# STM32F439ZIY6 register map
File version: 1.0
Registers are 32-bit, access not given, reset 0x0 unless marked. A register's access mark holds for its fields unless they carry their own. Offsets are from the block's base; [hi:lo] are bit positions; {n}, {i} and the like mark numbered series; 'fields as' and 'values as' point back to an identical list.

## DCMI
Base 0x50050000
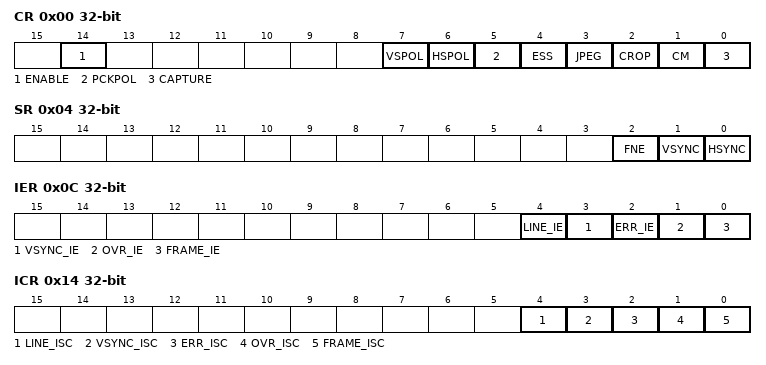
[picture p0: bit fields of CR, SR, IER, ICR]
0x00 CR
  [14] ENABLE, [7] VSPOL, [6] HSPOL, [5] PCKPOL, [4] ESS, [3] JPEG, [2] CROP, [1] CM, [0] CAPTURE
0x04 SR
  [2] FNE, [1] VSYNC, [0] HSYNC
0x08 RISR
0x0C IER
  [4] LINE_IE, [3] VSYNC_IE, [2] ERR_IE, [1] OVR_IE, [0] FRAME_IE
0x10 MISR
0x14 ICR
  [4] LINE_ISC, [3] VSYNC_ISC, [2] ERR_ISC, [1] OVR_ISC, [0] FRAME_ISC
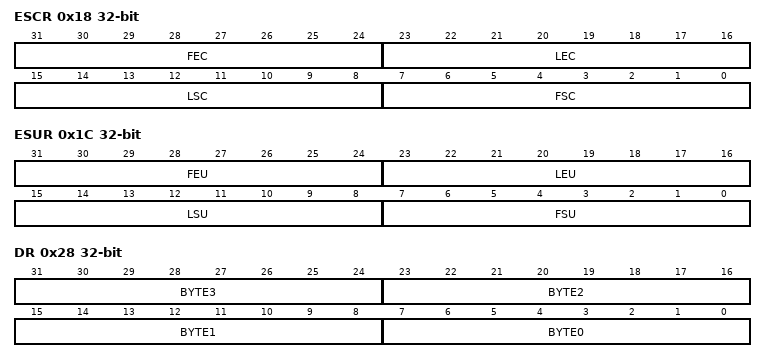
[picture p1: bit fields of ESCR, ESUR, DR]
0x18 ESCR
  [31:24] FEC, [23:16] LEC, [15:8] LSC, [7:0] FSC
0x1C ESUR
  [31:24] FEU, [23:16] LEU, [15:8] LSU, [7:0] FSU
0x20 CWSTRTR
0x24 CWSIZER
0x28 DR
  [8n+7:8n] BYTE{n} (n=0..3)

## CRYP
Base 0x50060000
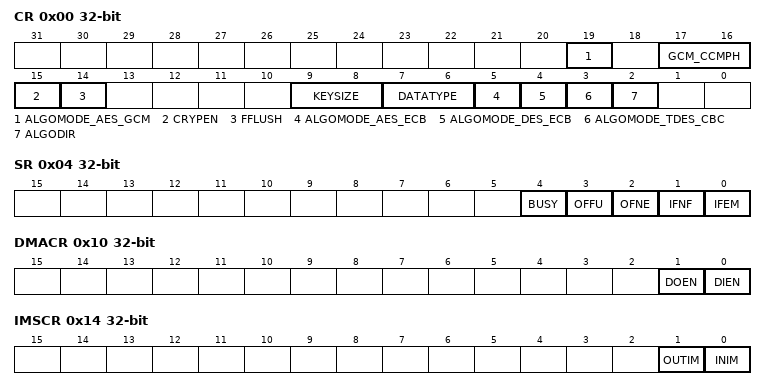
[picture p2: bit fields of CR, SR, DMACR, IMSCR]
0x00 CR
  [19] ALGOMODE_AES_GCM, [17:16] GCM_CCMPH, [15] CRYPEN, [14] FFLUSH, [9:8] KEYSIZE, [7:6] DATATYPE, [5] ALGOMODE_AES_ECB, [4] ALGOMODE_DES_ECB, [3] ALGOMODE_TDES_CBC, [2] ALGODIR
0x04 SR
  [4] BUSY, [3] OFFU, [2] OFNE, [1] IFNF, [0] IFEM
0x08 DIN
0x0C DOUT
0x10 DMACR
  [1] DOEN, [0] DIEN
0x14 IMSCR
  [1] OUTIM, [0] INIM
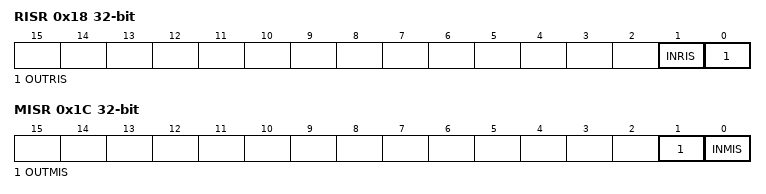
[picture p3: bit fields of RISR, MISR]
0x18 RISR
  [1] INRIS, [0] OUTRIS
0x1C MISR
  [1] OUTMIS, [0] INMIS
{0x20+8i} K{i}LR (i=0..3)
{0x24+8i} K{i}RR (i=0..3)
0x40 IV0LR
0x44 IV0RR
0x48 IV1LR
0x4C IV1RR
{0x50+4i} CSGCMCCM{i}R (i=0..7)
{0x70+4i} CSGCM{i}R (i=0..7)

## HASH
Base 0x50060400
0x00 CR
  [16] LKEY, [13] MDMAT, [12] DINNE, [11:8] NBW, [18:7] ALGO, [6] MODE, [5:4] DATATYPE, [3] DMAE, [2] INIT
0x04 DIN
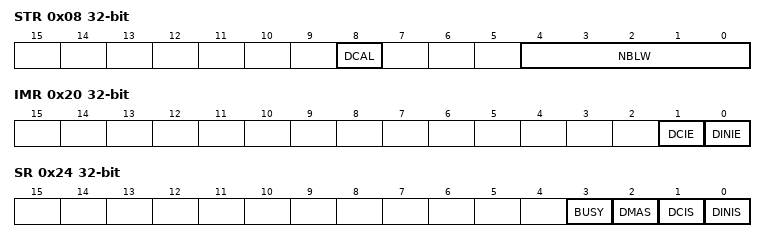
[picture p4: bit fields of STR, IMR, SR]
0x08 STR
  [8] DCAL, [4:0] NBLW
0x0C HR.0
0x10 HR.1
0x14 HR.2
0x18 HR.3
0x1C HR.4
0x20 IMR
  [1] DCIE, [0] DINIE
0x24 SR
  [3] BUSY, [2] DMAS, [1] DCIS, [0] DINIS
0xF8 CSR.0
0xFC CSR.1
0x100 CSR.2
0x104 CSR.3
0x108 CSR.4
0x10C CSR.5
0x110 CSR.6
0x114 CSR.7
0x118 CSR.8
0x11C CSR.9
0x120 CSR.10
0x124 CSR.11
0x128 CSR.12
0x12C CSR.13
0x130 CSR.14
0x134 CSR.15
0x138 CSR.16
0x13C CSR.17
0x140 CSR.18
0x144 CSR.19
0x148 CSR.20
0x14C CSR.21
0x150 CSR.22
0x154 CSR.23
0x158 CSR.24
0x15C CSR.25
0x160 CSR.26
0x164 CSR.27
0x168 CSR.28
0x16C CSR.29
0x170 CSR.30
0x174 CSR.31
0x178 CSR.32
0x17C CSR.33
0x180 CSR.34
0x184 CSR.35
0x188 CSR.36
0x18C CSR.37
0x190 CSR.38
0x194 CSR.39
0x198 CSR.40
0x19C CSR.41
0x1A0 CSR.42
0x1A4 CSR.43
0x1A8 CSR.44
0x1AC CSR.45
0x1B0 CSR.46
0x1B4 CSR.47
0x1B8 CSR.48
0x1BC CSR.49
0x1C0 CSR.50
0x1C4 CSR.51
0x1C8 CSR.52
0x1CC CSR.53

## HASH_DIGEST
Base 0x50060710
0x00 HR.0
0x04 HR.1
0x08 HR.2
0x0C HR.3
0x10 HR.4
0x14 HR.5
0x18 HR.6
0x1C HR.7

## RNG
Base 0x50060800
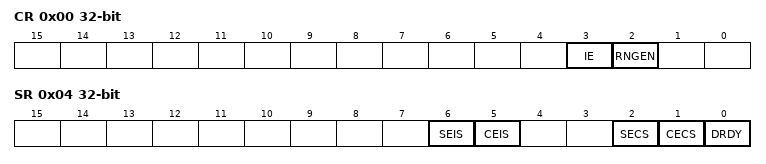
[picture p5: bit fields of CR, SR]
0x00 CR
  [3] IE, [2] RNGEN
0x04 SR
  [6] SEIS, [5] CEIS, [2] SECS, [1] CECS, [0] DRDY
0x08 DR

## FMC_Bank1
Base 0xA0000000
0x00 BTCR.0
0x04 BTCR.1
0x08 BTCR.2
0x0C BTCR.3
0x10 BTCR.4
0x14 BTCR.5
0x18 BTCR.6
0x1C BTCR.7

## FMC_Bank2_3
Base 0xA0000060
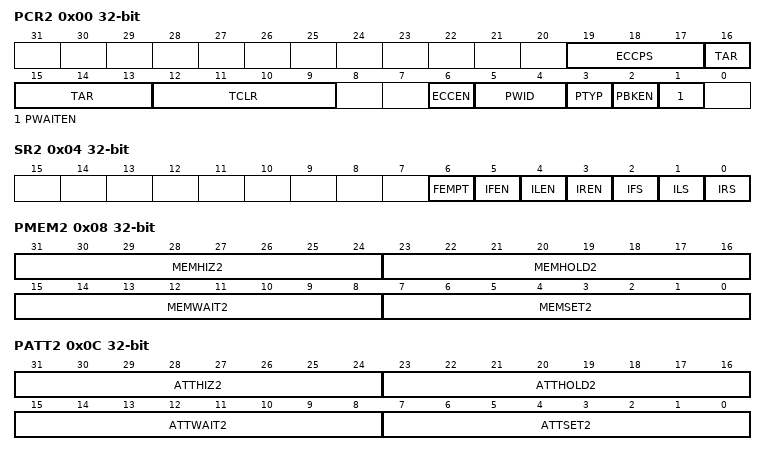
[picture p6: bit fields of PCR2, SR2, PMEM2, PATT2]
0x00 PCR2
  [19:17] ECCPS, [16:13] TAR, [12:9] TCLR, [6] ECCEN, [5:4] PWID, [3] PTYP, [2] PBKEN, [1] PWAITEN
0x04 SR2
  [6] FEMPT, [5] IFEN, [4] ILEN, [3] IREN, [2] IFS, [1] ILS, [0] IRS
0x08 PMEM2
  [31:24] MEMHIZ2, [23:16] MEMHOLD2, [15:8] MEMWAIT2, [7:0] MEMSET2
0x0C PATT2
  [31:24] ATTHIZ2, [23:16] ATTHOLD2, [15:8] ATTWAIT2, [7:0] ATTSET2
0x14 ECCR2
  [31:0] ECC2
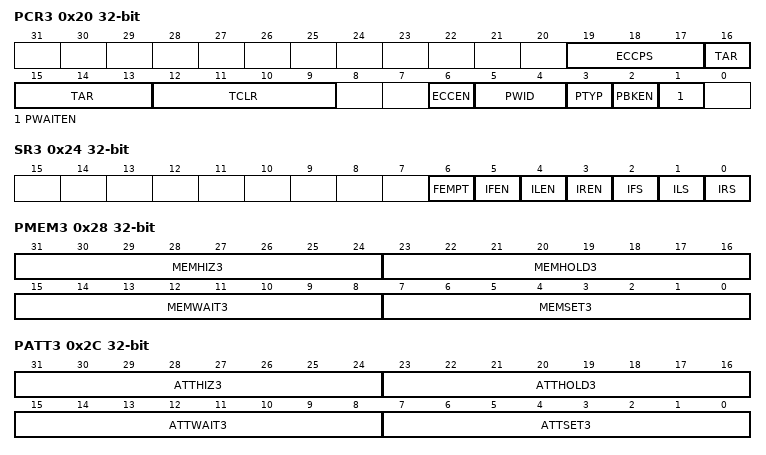
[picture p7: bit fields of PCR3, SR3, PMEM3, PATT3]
0x20 PCR3
  fields as PCR2
0x24 SR3
  [6] FEMPT, [5] IFEN, [4] ILEN, [3] IREN, [2] IFS, [1] ILS, [0] IRS
0x28 PMEM3
  [31:24] MEMHIZ3, [23:16] MEMHOLD3, [15:8] MEMWAIT3, [7:0] MEMSET3
0x2C PATT3
  [31:24] ATTHIZ3, [23:16] ATTHOLD3, [15:8] ATTWAIT3, [7:0] ATTSET3
0x34 ECCR3
  [31:0] ECC3

## FMC_Bank4
Base 0xA00000A0
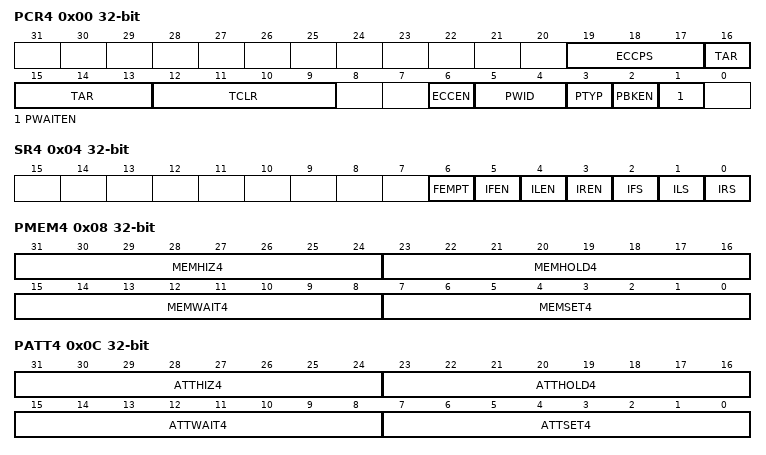
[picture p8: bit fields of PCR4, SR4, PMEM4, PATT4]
0x00 PCR4
  [19:17] ECCPS, [16:13] TAR, [12:9] TCLR, [6] ECCEN, [5:4] PWID, [3] PTYP, [2] PBKEN, [1] PWAITEN
0x04 SR4
  [6] FEMPT, [5] IFEN, [4] ILEN, [3] IREN, [2] IFS, [1] ILS, [0] IRS
0x08 PMEM4
  [31:24] MEMHIZ4, [23:16] MEMHOLD4, [15:8] MEMWAIT4, [7:0] MEMSET4
0x0C PATT4
  [31:24] ATTHIZ4, [23:16] ATTHOLD4, [15:8] ATTWAIT4, [7:0] ATTSET4
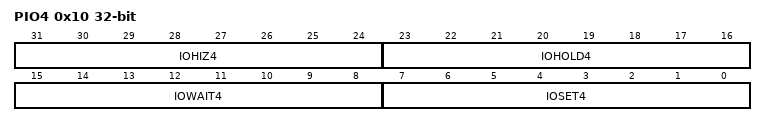
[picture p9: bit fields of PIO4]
0x10 PIO4
  [31:24] IOHIZ4, [23:16] IOHOLD4, [15:8] IOWAIT4, [7:0] IOSET4

## FMC_Bank1E
Base 0xA0000104
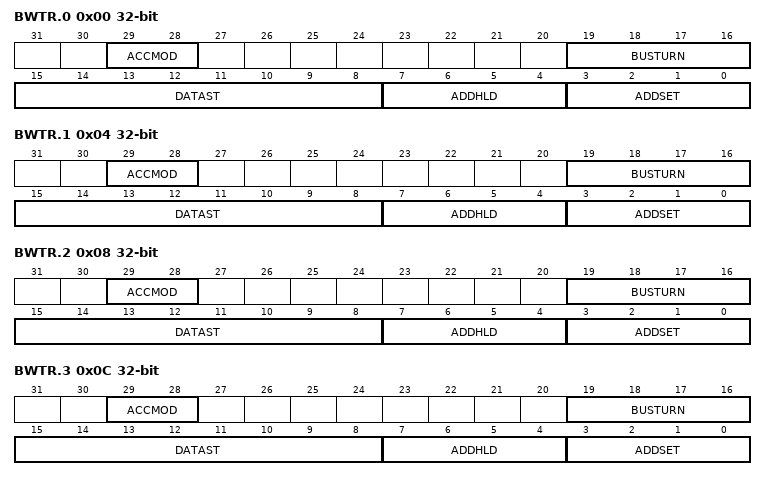
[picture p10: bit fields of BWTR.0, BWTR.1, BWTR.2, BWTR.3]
0x00 BWTR.0
  [29:28] ACCMOD, [19:16] BUSTURN, [15:8] DATAST, [7:4] ADDHLD, [3:0] ADDSET
0x04 BWTR.1
  fields as BWTR.0
0x08 BWTR.2
  fields as BWTR.0
0x0C BWTR.3
  fields as BWTR.0
0x10 BWTR.4
0x14 BWTR.5
0x18 BWTR.6

## FMC_Bank5_6
Base 0xA0000140
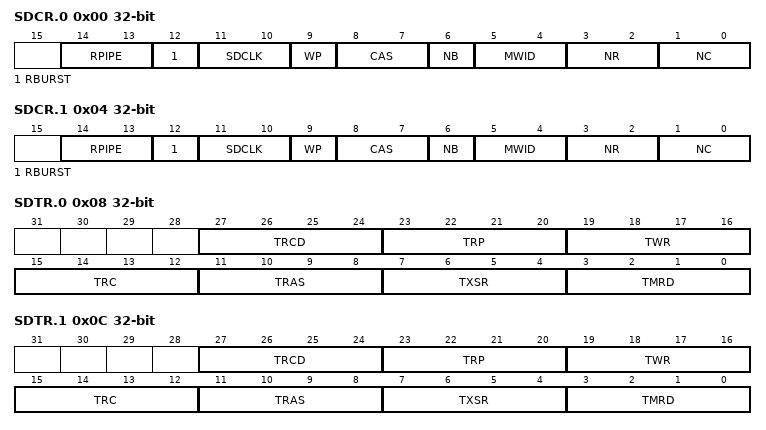
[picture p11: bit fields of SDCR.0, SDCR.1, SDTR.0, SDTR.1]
0x00 SDCR.0
  [14:13] RPIPE, [12] RBURST, [11:10] SDCLK, [9] WP, [8:7] CAS, [6] NB, [5:4] MWID, [3:2] NR, [1:0] NC
0x04 SDCR.1
  fields as SDCR.0
0x08 SDTR.0
  [27:24] TRCD, [23:20] TRP, [19:16] TWR, [15:12] TRC, [11:8] TRAS, [7:4] TXSR, [3:0] TMRD
0x0C SDTR.1
  fields as SDTR.0
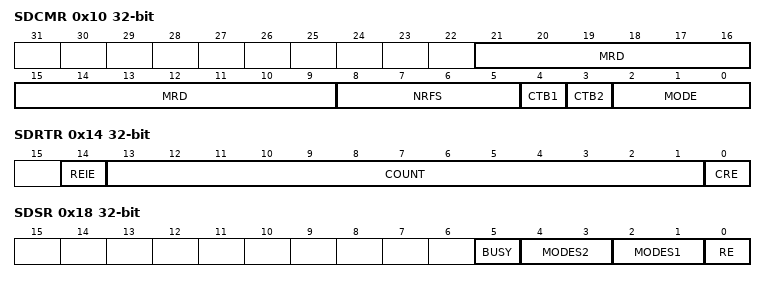
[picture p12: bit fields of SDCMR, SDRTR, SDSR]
0x10 SDCMR
  [21:9] MRD, [8:5] NRFS, [4] CTB1, [3] CTB2, [2:0] MODE
0x14 SDRTR
  [14] REIE, [13:1] COUNT, [0] CRE
0x18 SDSR
  [5] BUSY, [4:3] MODES2, [2:1] MODES1, [0] RE

## DBGMCU
Base 0xE0042000
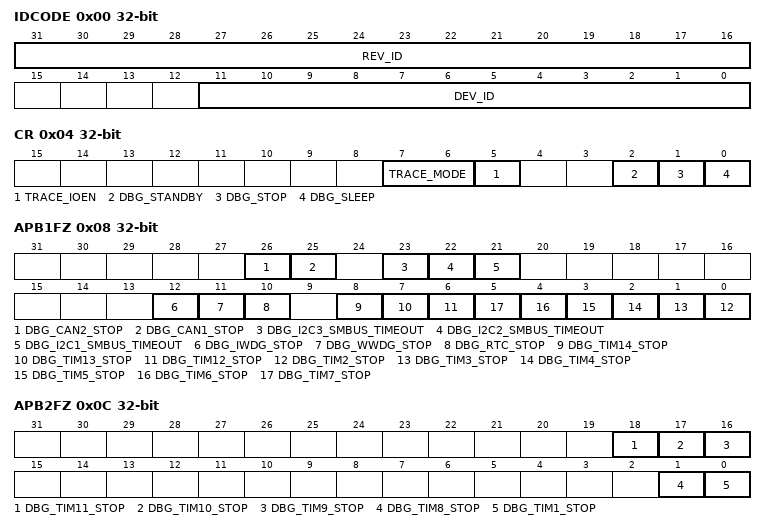
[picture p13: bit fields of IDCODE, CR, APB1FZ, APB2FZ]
0x00 IDCODE
  [31:16] REV_ID, [11:0] DEV_ID
0x04 CR
  [7:6] TRACE_MODE, [5] TRACE_IOEN, [2] DBG_STANDBY, [1] DBG_STOP, [0] DBG_SLEEP
0x08 APB1FZ
  [26] DBG_CAN2_STOP, [25] DBG_CAN1_STOP, [23] DBG_I2C3_SMBUS_TIMEOUT, [22] DBG_I2C2_SMBUS_TIMEOUT, [21] DBG_I2C1_SMBUS_TIMEOUT, [12] DBG_IWDG_STOP, [11] DBG_WWDG_STOP, [10] DBG_RTC_STOP, [8] DBG_TIM14_STOP, [7] DBG_TIM13_STOP, [6] DBG_TIM12_STOP, [n-2] DBG_TIM{n}_STOP (n=2..7)
0x0C APB2FZ
  [18] DBG_TIM11_STOP, [17] DBG_TIM10_STOP, [16] DBG_TIM9_STOP, [1] DBG_TIM8_STOP, [0] DBG_TIM1_STOP
